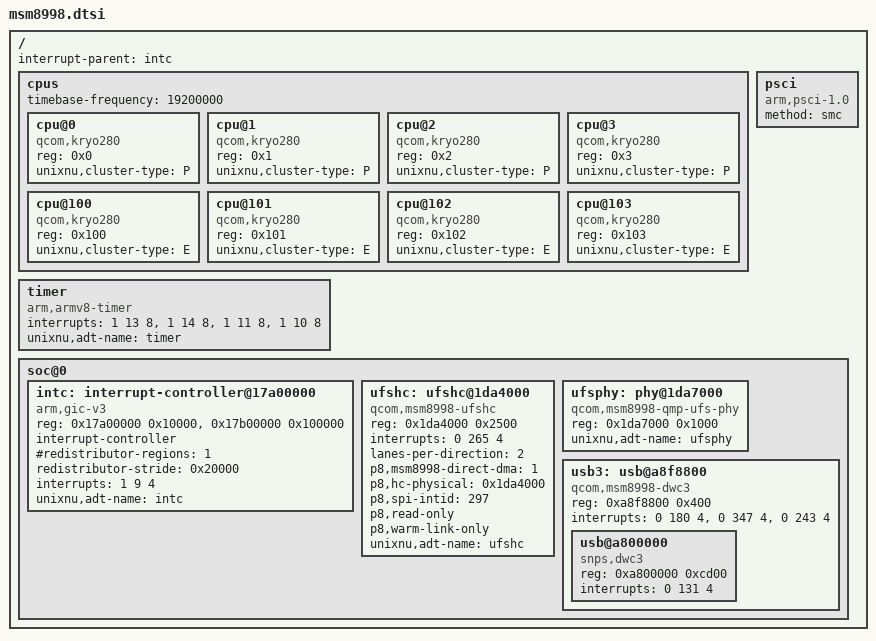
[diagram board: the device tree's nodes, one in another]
/ {
    #address-cells = <2>;
    #size-cells = <2>;
    interrupt-parent = <&intc>;

    cpus {
        #address-cells = <1>;
        #size-cells = <0>;
        timebase-frequency = <19200000>;

        cpu@0 {
            device_type = "cpu";
            compatible = "qcom,kryo280";
            reg = <0x0>;
            unixnu,cluster-type = "P";
        };

        cpu@1 {
            device_type = "cpu";
            compatible = "qcom,kryo280";
            reg = <0x1>;
            unixnu,cluster-type = "P";
        };

        cpu@2 {
            device_type = "cpu";
            compatible = "qcom,kryo280";
            reg = <0x2>;
            unixnu,cluster-type = "P";
        };

        cpu@3 {
            device_type = "cpu";
            compatible = "qcom,kryo280";
            reg = <0x3>;
            unixnu,cluster-type = "P";
        };

        cpu@100 {
            device_type = "cpu";
            compatible = "qcom,kryo280";
            reg = <0x100>;
            unixnu,cluster-type = "E";
        };

        cpu@101 {
            device_type = "cpu";
            compatible = "qcom,kryo280";
            reg = <0x101>;
            unixnu,cluster-type = "E";
        };

        cpu@102 {
            device_type = "cpu";
            compatible = "qcom,kryo280";
            reg = <0x102>;
            unixnu,cluster-type = "E";
        };

        cpu@103 {
            device_type = "cpu";
            compatible = "qcom,kryo280";
            reg = <0x103>;
            unixnu,cluster-type = "E";
        };
    };

    psci {
        compatible = "arm,psci-1.0";
        method = "smc";
    };

    timer {
        compatible = "arm,armv8-timer";
        interrupts = <1 13 8>, <1 14 8>, <1 11 8>, <1 10 8>;
        unixnu,adt-name = "timer";
    };

    soc@0 {
        #address-cells = <1>;
        #size-cells = <1>;
        ranges = <0x0 0x0 0x0 0xffffffff>;

        intc: interrupt-controller@17a00000 {
            compatible = "arm,gic-v3";
            reg = <0x17a00000 0x10000>, <0x17b00000 0x100000>;
            #interrupt-cells = <3>;
            #address-cells = <1>;
            #size-cells = <1>;
            ranges;
            interrupt-controller;
            #redistributor-regions = <1>;
            redistributor-stride = <0x20000>;
            interrupts = <1 9 4>;
            unixnu,adt-name = "intc";
        };

        ufshc: ufshc@1da4000 {
            compatible = "qcom,msm8998-ufshc", "qcom,ufshc", "jedec,ufs-2.0";
            reg = <0x1da4000 0x2500>;
            interrupts = <0 265 4>;
            clock-names = "core_clk", "bus_aggr_clk", "iface_clk",
                          "core_clk_unipro", "ref_clk",
                          "tx_lane0_sync_clk", "rx_lane0_sync_clk",
                          "rx_lane1_sync_clk";
            phy-names = "ufsphy";
            lanes-per-direction = <2>;
            p8,msm8998-direct-dma = <1>;
            p8,hc-physical = <0x1da4000>;
            p8,spi-intid = <297>;
            p8,read-only;
            p8,warm-link-only;
            status = "okay";
            unixnu,adt-name = "ufshc";
        };

        ufsphy: phy@1da7000 {
            compatible = "qcom,msm8998-qmp-ufs-phy";
            reg = <0x1da7000 0x1000>;
            #phy-cells = <0>;
            status = "okay";
            unixnu,adt-name = "ufsphy";
        };

        usb3: usb@a8f8800 {
            compatible = "qcom,msm8998-dwc3", "qcom,dwc3";
            reg = <0xa8f8800 0x400>;
            interrupts = <0 180 4>, <0 347 4>, <0 243 4>;
            #address-cells = <1>;
            #size-cells = <1>;
            ranges;
            status = "okay";

            usb@a800000 {
                compatible = "snps,dwc3";
                reg = <0xa800000 0xcd00>;
                interrupts = <0 131 4>;
            };
        };
    };
};
